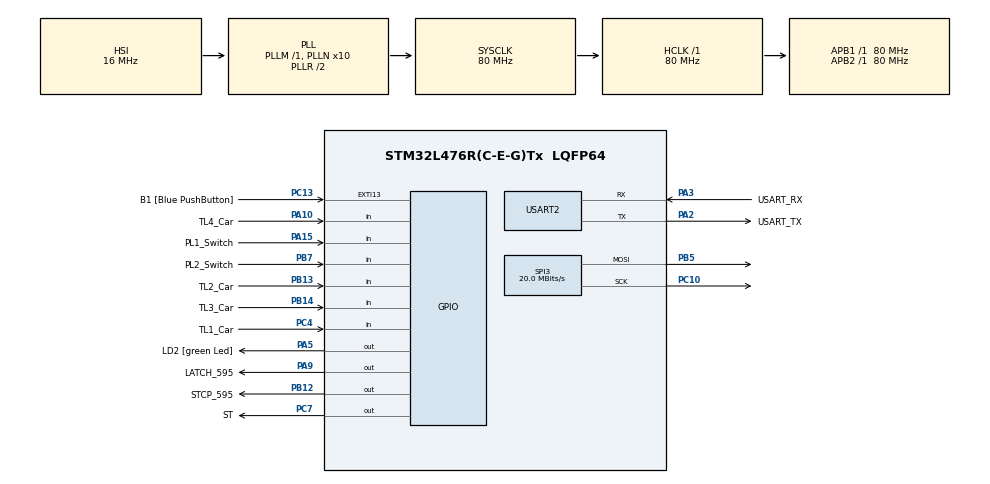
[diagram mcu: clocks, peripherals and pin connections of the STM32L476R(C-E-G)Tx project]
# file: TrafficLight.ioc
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Mcu.Family=STM32L4
Mcu.Name=STM32L476R(C-E-G)Tx
Mcu.Package=LQFP64
NVIC.PriorityGroup=NVIC_PRIORITYGROUP_4
PA10.GPIO_Label=TL4_Car
PA10.Signal=GPIO_Input
PA13\ (JTMS-SWDIO).GPIO_Label=TMS
PA13\ (JTMS-SWDIO).Mode=Serial_Wire
PA13\ (JTMS-SWDIO).Signal=SYS_JTMS-SWDIO
PA14\ (JTCK-SWCLK).GPIO_Label=TCK
PA14\ (JTCK-SWCLK).Mode=Serial_Wire
PA14\ (JTCK-SWCLK).Signal=SYS_JTCK-SWCLK
PA15\ (JTDI).GPIO_Label=PL1_Switch
PA15\ (JTDI).GPIO_PuPd=GPIO_PULLUP
PA15\ (JTDI).Signal=GPIO_Input
PA2.GPIO_Label=USART_TX
PA2.GPIO_Mode=GPIO_MODE_AF_PP
PA2.GPIO_PuPd=GPIO_NOPULL
PA2.GPIO_Speed=GPIO_SPEED_FREQ_VERY_HIGH
PA2.Mode=Asynchronous
PA2.Signal=USART2_TX
PA3.GPIO_Label=USART_RX
PA3.GPIO_Mode=GPIO_MODE_AF_PP
PA3.GPIO_PuPd=GPIO_NOPULL
PA3.GPIO_Speed=GPIO_SPEED_FREQ_VERY_HIGH
PA3.Mode=Asynchronous
PA3.Signal=USART2_RX
PA5.GPIO_Label=LD2 [green Led]
PA5.GPIO_ModeDefaultOutputPP=GPIO_MODE_OUTPUT_PP
PA5.GPIO_PuPd=GPIO_NOPULL
PA5.GPIO_Speed=GPIO_SPEED_FREQ_LOW
PA5.Signal=GPIO_Output
PA9.GPIO_Label=LATCH_595
PA9.GPIO_Speed=GPIO_SPEED_FREQ_LOW
PA9.PinState=GPIO_PIN_SET
PA9.Signal=GPIO_Output
PB12.GPIO_Label=STCP_595
PB12.Signal=GPIO_Output
PB13.GPIO_Label=TL2_Car
PB13.Signal=GPIO_Input
PB14.GPIO_Label=TL3_Car
PB14.Signal=GPIO_Input
PB3\ (JTDO-TRACESWO).GPIO_Label=SWO
PB3\ (JTDO-TRACESWO).Signal=SYS_JTDO-SWO
PB5.Mode=TX_Only_Simplex_Unidirect_Master
PB5.Signal=SPI3_MOSI
PB7.GPIO_Label=PL2_Switch
PB7.GPIO_PuPd=GPIO_PULLUP
PB7.Signal=GPIO_Input
PC10.Mode=TX_Only_Simplex_Unidirect_Master
PC10.Signal=SPI3_SCK
PC13.GPIO_Label=B1 [Blue PushButton]
PC13.GPIO_ModeDefaultEXTI=GPIO_MODE_IT_FALLING
PC13.GPIO_PuPd=GPIO_NOPULL
PC13.Signal=GPXTI13
PC14-OSC32_IN\ (PC14).Mode=LSE-External-Oscillator
PC14-OSC32_IN\ (PC14).Signal=RCC_OSC32_IN
PC15-OSC32_OUT\ (PC15).Mode=LSE-External-Oscillator
PC15-OSC32_OUT\ (PC15).Signal=RCC_OSC32_OUT
PC4.GPIO_Label=TL1_Car
PC4.GPIO_PuPd=GPIO_NOPULL
PC4.Signal=GPIO_Input
PC7.GPIO_Label=ST
PC7.Signal=GPIO_Output
PH0-OSC_IN\ (PH0).Signal=RCC_OSC_IN
PH1-OSC_OUT\ (PH1).Signal=RCC_OSC_OUT
ProjectManager.HeapSize=0x200
ProjectManager.StackSize=0x400
ProjectManager.TargetToolchain=STM32CubeIDE
RCC.ADCFreq_Value=64000000
RCC.AHBFreq_Value=80000000
RCC.APB1Freq_Value=80000000
RCC.APB1TimFreq_Value=80000000
RCC.APB2Freq_Value=80000000
RCC.APB2TimFreq_Value=80000000
RCC.CortexFreq_Value=80000000
RCC.HCLKFreq_Value=80000000
RCC.HSE_VALUE=8000000
RCC.HSI_VALUE=16000000
RCC.MSI_VALUE=4000000
RCC.PLLN=10
RCC.PLLSourceVirtual=RCC_PLLSOURCE_HSI
RCC.PREFETCH_ENABLE=1
RCC.SYSCLKFreq_VALUE=80000000
RCC.SYSCLKSource=RCC_SYSCLKSOURCE_PLLCLK
RCC.USBFreq_Value=64000000
RCC.VCOOutputFreq_Value=160000000
SPI3.BaudRatePrescaler=SPI_BAUDRATEPRESCALER_4
SPI3.CalculateBaudRate=20.0 MBits/s
SPI3.DataSize=SPI_DATASIZE_8BIT
SPI3.Direction=SPI_DIRECTION_2LINES
SPI3.Mode=SPI_MODE_MASTER
SPI3.VirtualType=VM_MASTER
USART2.VirtualMode-Asynchronous=VM_ASYNC
board=NUCLEO-L476RG

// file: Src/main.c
/* USER CODE BEGIN Header */
/**
  ******************************************************************************
  * @file           : main.c
  * @brief          : Main program integrating Task 1 and Task 2 requirements
  ******************************************************************************
  * @attention
  *
  *
  ******************************************************************************
  */
/* USER CODE END Header */

#include "main.h"
#include "spi.h"
#include "usart.h"
#include "gpio.h"

/* USER CODE BEGIN Includes */
#include "trafficlight.h"
#include "test.h"
/* USER CODE END Includes */

/* USER CODE BEGIN PD */
//#define RUN_TEST_PROGRAM
/* USER CODE END PD */

void SystemClock_Config(void);

int main(void)
{

    HAL_Init();
    SystemClock_Config();
    MX_GPIO_Init();
    MX_USART2_UART_Init();
    MX_SPI3_Init();

    /* USER CODE BEGIN 2 */
#ifdef RUN_TEST_PROGRAM
#include "trafficlight.h"
    test_program();
#else
    traffic_light_sys();
#endif
    /* USER CODE END 2 */

    /* Infinite loop */
    while (1)
    {
        /* USER CODE BEGIN 3 */
        // Additional user code if needed
        /* USER CODE END 3 */
    }
}

void SystemClock_Config(void)
{
    /* This is auto-generated code from CubeMX and is omitted for brevity. */
    /* Ensure your clock is configured as needed. */
    RCC_OscInitTypeDef RCC_OscInitStruct = {0};
    RCC_ClkInitTypeDef RCC_ClkInitStruct = {0};
    HAL_PWREx_ControlVoltageScaling(PWR_REGULATOR_VOLTAGE_SCALE1);
    RCC_OscInitStruct.OscillatorType = RCC_OSCILLATORTYPE_HSI;
    RCC_OscInitStruct.HSIState = RCC_HSI_ON;
    RCC_OscInitStruct.HSICalibrationValue = RCC_HSICALIBRATION_DEFAULT;
    RCC_OscInitStruct.PLL.PLLState = RCC_PLL_ON;
    RCC_OscInitStruct.PLL.PLLSource = RCC_PLLSOURCE_HSI;
    RCC_OscInitStruct.PLL.PLLM = 1;
    RCC_OscInitStruct.PLL.PLLN = 10;
    RCC_OscInitStruct.PLL.PLLP = RCC_PLLP_DIV7;
    RCC_OscInitStruct.PLL.PLLQ = RCC_PLLQ_DIV2;
    RCC_OscInitStruct.PLL.PLLR = RCC_PLLR_DIV2;
    HAL_RCC_OscConfig(&RCC_OscInitStruct);
    RCC_ClkInitStruct.ClockType = RCC_CLOCKTYPE_HCLK | RCC_CLOCKTYPE_SYSCLK
        | RCC_CLOCKTYPE_PCLK1 | RCC_CLOCKTYPE_PCLK2;
    RCC_ClkInitStruct.SYSCLKSource = RCC_SYSCLKSOURCE_PLLCLK;
    RCC_ClkInitStruct.AHBCLKDivider = RCC_SYSCLK_DIV1;
    RCC_ClkInitStruct.APB1CLKDivider = RCC_HCLK_DIV1;
    RCC_ClkInitStruct.APB2CLKDivider = RCC_HCLK_DIV1;
    HAL_RCC_ClockConfig(&RCC_ClkInitStruct, FLASH_LATENCY_4);
}

void Error_Handler(void)
{
    __disable_irq();
    while (1)
    {
    }
}
